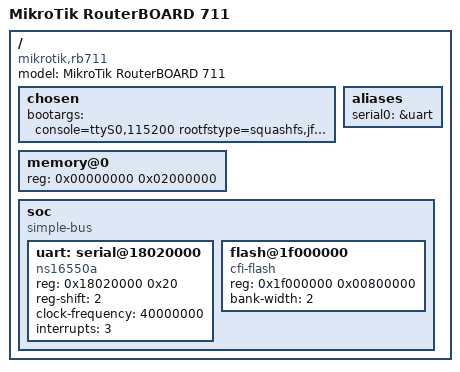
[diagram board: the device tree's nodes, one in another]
/dts-v1/;
/include/ "ar7241.dtsi"

/ {
    compatible = "mikrotik,rb711", "qca,ar7241";
    model = "MikroTik RouterBOARD 711";

    chosen {
        bootargs = "console=ttyS0,115200 rootfstype=squashfs,jffs2";
    };

    aliases {
        serial0 = &uart;
    };

    memory@0 {
        device_type = "memory";
        reg = <0x00000000 0x02000000>;  /* 32MB RAM */
    };

    soc {
        #address-cells = <1>;
        #size-cells = <1>;
        compatible = "simple-bus";
        ranges;

        uart: serial@18020000 {
            compatible = "ns16550a";
            reg = <0x18020000 0x20>;
            reg-shift = <2>;
            clock-frequency = <40000000>;
            interrupts = <3>;
        };

        flash@1f000000 {
            compatible = "cfi-flash";
            reg = <0x1f000000 0x00800000>; /* 8MB flash */
            bank-width = <2>;
        };
    };
};
